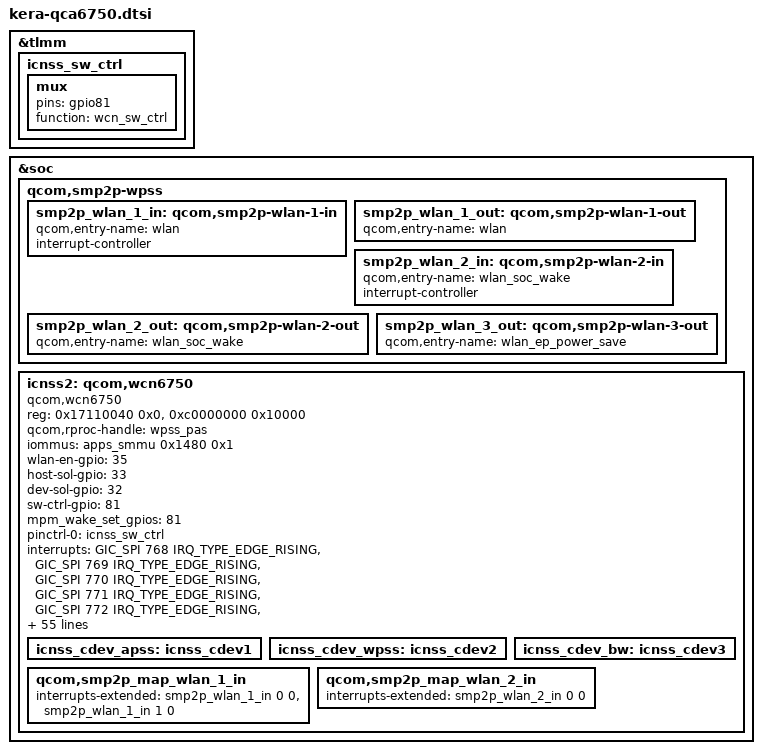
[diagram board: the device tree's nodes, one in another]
// SPDX-License-Identifier: BSD-3-Clause

/*
 * Copyright (c) 2024-2025 Qualcomm Innovation Center, Inc. All rights reserved.
 */

#include <dt-bindings/interrupt-controller/arm-gic.h>

&tlmm {
	icnss_sw_ctrl: icnss_sw_ctrl {
		mux {
			pins = "gpio81";
			function = "wcn_sw_ctrl";
		};
	};
};

&soc {
	qcom,smp2p-wpss {
		smp2p_wlan_1_in: qcom,smp2p-wlan-1-in {
			qcom,entry-name = "wlan";
			interrupt-controller;
			#interrupt-cells = <2>;
		};

		smp2p_wlan_1_out: qcom,smp2p-wlan-1-out {
			qcom,entry-name = "wlan";
			#qcom,smem-state-cells = <1>;
		};

		smp2p_wlan_2_in: qcom,smp2p-wlan-2-in {
			qcom,entry-name = "wlan_soc_wake";
			interrupt-controller;
			#interrupt-cells = <2>;
		};

		smp2p_wlan_2_out: qcom,smp2p-wlan-2-out {
			qcom,entry-name = "wlan_soc_wake";
			#qcom,smem-state-cells = <1>;
		};

		smp2p_wlan_3_out: qcom,smp2p-wlan-3-out {
			qcom,entry-name = "wlan_ep_power_save";
			#qcom,smem-state-cells = <1>;
		};
	};

	icnss2: qcom,wcn6750 {
		compatible = "qcom,wcn6750";
		reg = <0x17110040 0x0>,
		      <0xc0000000 0x10000>;
		reg-names = "msi_addr", "smmu_iova_ipa";
		qcom,rproc-handle = <&wpss_pas>;
		iommus = <&apps_smmu 0x1480 0x1>;
		wlan-en-gpio = <35>;
		host-sol-gpio = <33>;
		dev-sol-gpio = <32>;
		sw-ctrl-gpio = <81>;
		/* List of GPIOs to be setup for interrupt wakeup capable */
		mpm_wake_set_gpios = <81>;
		pinctrl-names = "sw_ctrl";
		pinctrl-0 = <&icnss_sw_ctrl>;

		interrupts = <GIC_SPI 768 IRQ_TYPE_EDGE_RISING>,
			     <GIC_SPI 769 IRQ_TYPE_EDGE_RISING>,
			     <GIC_SPI 770 IRQ_TYPE_EDGE_RISING>,
			     <GIC_SPI 771 IRQ_TYPE_EDGE_RISING>,
			     <GIC_SPI 772 IRQ_TYPE_EDGE_RISING>,
			     <GIC_SPI 773 IRQ_TYPE_EDGE_RISING>,
			     <GIC_SPI 774 IRQ_TYPE_EDGE_RISING>,
			     <GIC_SPI 775 IRQ_TYPE_EDGE_RISING>,
			     <GIC_SPI 776 IRQ_TYPE_EDGE_RISING>,
			     <GIC_SPI 777 IRQ_TYPE_EDGE_RISING>,
			     <GIC_SPI 778 IRQ_TYPE_EDGE_RISING>,
			     <GIC_SPI 779 IRQ_TYPE_EDGE_RISING>,
			     <GIC_SPI 780 IRQ_TYPE_EDGE_RISING>,
			     <GIC_SPI 781 IRQ_TYPE_EDGE_RISING>,
			     <GIC_SPI 782 IRQ_TYPE_EDGE_RISING>,
			     <GIC_SPI 783 IRQ_TYPE_EDGE_RISING>,
			     <GIC_SPI 784 IRQ_TYPE_EDGE_RISING>,
			     <GIC_SPI 785 IRQ_TYPE_EDGE_RISING>,
			     <GIC_SPI 786 IRQ_TYPE_EDGE_RISING>,
			     <GIC_SPI 787 IRQ_TYPE_EDGE_RISING>,
			     <GIC_SPI 788 IRQ_TYPE_EDGE_RISING>,
			     <GIC_SPI 789 IRQ_TYPE_EDGE_RISING>,
			     <GIC_SPI 790 IRQ_TYPE_EDGE_RISING>,
			     <GIC_SPI 791 IRQ_TYPE_EDGE_RISING>,
			     <GIC_SPI 792 IRQ_TYPE_EDGE_RISING>,
			     <GIC_SPI 793 IRQ_TYPE_EDGE_RISING>,
			     <GIC_SPI 794 IRQ_TYPE_EDGE_RISING>,
			     <GIC_SPI 795 IRQ_TYPE_EDGE_RISING>,
			     <GIC_SPI 796 IRQ_TYPE_EDGE_RISING>,
			     <GIC_SPI 797 IRQ_TYPE_EDGE_RISING>,
			     <GIC_SPI 798 IRQ_TYPE_EDGE_RISING>,
			     <GIC_SPI 799 IRQ_TYPE_EDGE_RISING>;

		qcom,iommu-dma = "fastmap";
		qcom,iommu-faults = "stall-disable", "HUPCF", "non-fatal";
		qcom,iommu-dma-addr-pool = <0xb0000000 0x10000000>;
		qcom,iommu-geometry = <0xb0000000 0x10010000>;
		dma-coherent;
		pin-ctrl-support;
		qcom,fw-prefix;
		qcom,wlan;
		tsens = "sys-therm-3";
		wcn-hw-version = "qca6750";
		qcom,wlan-msa-fixed-region = <&wlan_msa_mem>;

		vdd-cx-mx-supply = <&S3B>;
		qcom,vdd-cx-mx-config = <920000 1040000 0 0 0>;
		vdd-1.8-xo-supply = <&S1B>;
		qcom,vdd-1.8-xo-config = <1856000 2040000 0 0 0>;
		vdd-1.3-rfa-supply = <&S2B>;
		qcom,vdd-1.3-rfa-config = <1256000 1408000 0 0 0>;
		vdd-1.8-io-supply = <&L11B>;
		qcom,vdd-1.8-io-config = <1800000 1800000 0 0 0>;

		qcom,smem-states = <&smp2p_wlan_1_out 0>,
				   <&smp2p_wlan_2_out 0>,
				   <&smp2p_wlan_3_out 0>;
		qcom,smem-state-names = "wlan-smp2p-out",
					"wlan-soc-wake-smp2p-out",
					"wlan-ep-powersave-smp2p-out";

		qcom,qmp = <&aoss_qmp>;
		qcom,vreg_ol_cpr ="s3b";

		icnss_cdev_apss: icnss_cdev1 {
			#cooling-cells = <2>;
		};

		icnss_cdev_wpss: icnss_cdev2 {
			#cooling-cells = <2>;
		};

		icnss_cdev_bw: icnss_cdev3 {
			#cooling-cells = <2>;
		};

		qcom,smp2p_map_wlan_1_in {
			interrupts-extended = <&smp2p_wlan_1_in 0 0>,
					      <&smp2p_wlan_1_in 1 0>;
			interrupt-names = "qcom,smp2p-force-fatal-error",
					  "qcom,smp2p-early-crash-ind";
		};

		qcom,smp2p_map_wlan_2_in {
			interrupts-extended = <&smp2p_wlan_2_in 0 0>;
			interrupt-names = "qcom,smp2p-soc-wake-ack";
		};
	};
};
